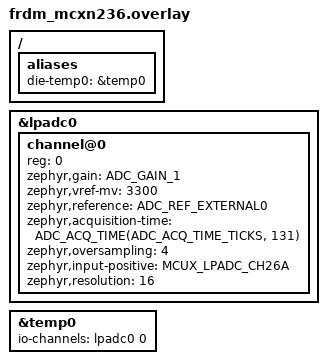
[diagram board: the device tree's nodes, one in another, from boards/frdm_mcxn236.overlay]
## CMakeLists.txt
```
cmake_minimum_required(VERSION 3.20.0)

# Pull in the Zephyr build system
find_package(Zephyr REQUIRED HINTS $ENV{ZEPHYR_BASE})

project(adc_silicon_temp)

# Export compile commands for clangd (Neovim)
set(CMAKE_EXPORT_COMPILE_COMMANDS ON)

target_sources(app PRIVATE src/main.c)
```

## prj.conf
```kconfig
# printk() enable for console output
# CONFIG_PRINTK=y

# Enable Logging 
CONFIG_LOG=y

# Enable GPIOS
# CONFIG_GPIO=y

# Enable ADC 
CONFIG_ADC=y

# Enable sensor 
CONFIG_SENSOR=y

# Floating point print support 
CONFIG_CBPRINTF_FP_SUPPORT=y
```

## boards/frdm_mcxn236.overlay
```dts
/* frdm_mcxn236.overlay */
#include <zephyr/dt-bindings/adc/adc.h>
#include <zephyr/dt-bindings/adc/mcux-lpadc.h>

/ {
	aliases {
		die-temp0 = &temp0;
	};
};

&lpadc0 {
	status = "okay";
	#address-cells = <1>;
	#size-cells = <0>;

	channel@0 {
		reg = <0>;
		
		/* Restored required gain property */
		zephyr,gain = "ADC_GAIN_1";
		
		zephyr,vref-mv = <3300>; 
		zephyr,reference = "ADC_REF_EXTERNAL0";
		zephyr,acquisition-time = <ADC_ACQ_TIME(ADC_ACQ_TIME_TICKS, 131)>;
		zephyr,oversampling = <4>; 
		zephyr,input-positive = <MCUX_LPADC_CH26A>;
		zephyr,resolution = <16>;
	};
};

&temp0 {
	status = "okay";
	io-channels = <&lpadc0 0>;
};
```

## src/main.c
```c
#include <zephyr/kernel.h>
#include <zephyr/drivers/sensor.h>
#include <zephyr/device.h>
#include <zephyr/logging/log.h>

LOG_MODULE_REGISTER(die_logger, LOG_LEVEL_INF);

int main(void)
{
  const struct device *const die_temp = DEVICE_DT_GET(DT_ALIAS(die_temp0));

  if (die_temp == NULL) {
    LOG_ERR("No nxp,lpadc-temp40 device found in devicetree");
    return -1;
  }

  if (!device_is_ready(die_temp)) {
    LOG_ERR("Device is not ready");
    return -1;
  }

  LOG_INF("Device %s is initialized successfully", die_temp -> name);

  while (1) {
    struct sensor_value silicon_temperature;

    if (sensor_sample_fetch(die_temp) < 0) {
      LOG_ERR("Failed to fetch sensor data");
      k_msleep(1000);
      continue;
    }

    if (sensor_channel_get(die_temp, SENSOR_CHAN_DIE_TEMP, &silicon_temperature) < 0) {
      LOG_ERR("Failed to get sensor channel");
      return -1;
    }

    double temp_c = sensor_value_to_double(&silicon_temperature);

    LOG_INF("Silicon Die Temperature: %.2f", temp_c);

    k_msleep(1000);
  }

  return 0;
}
```
